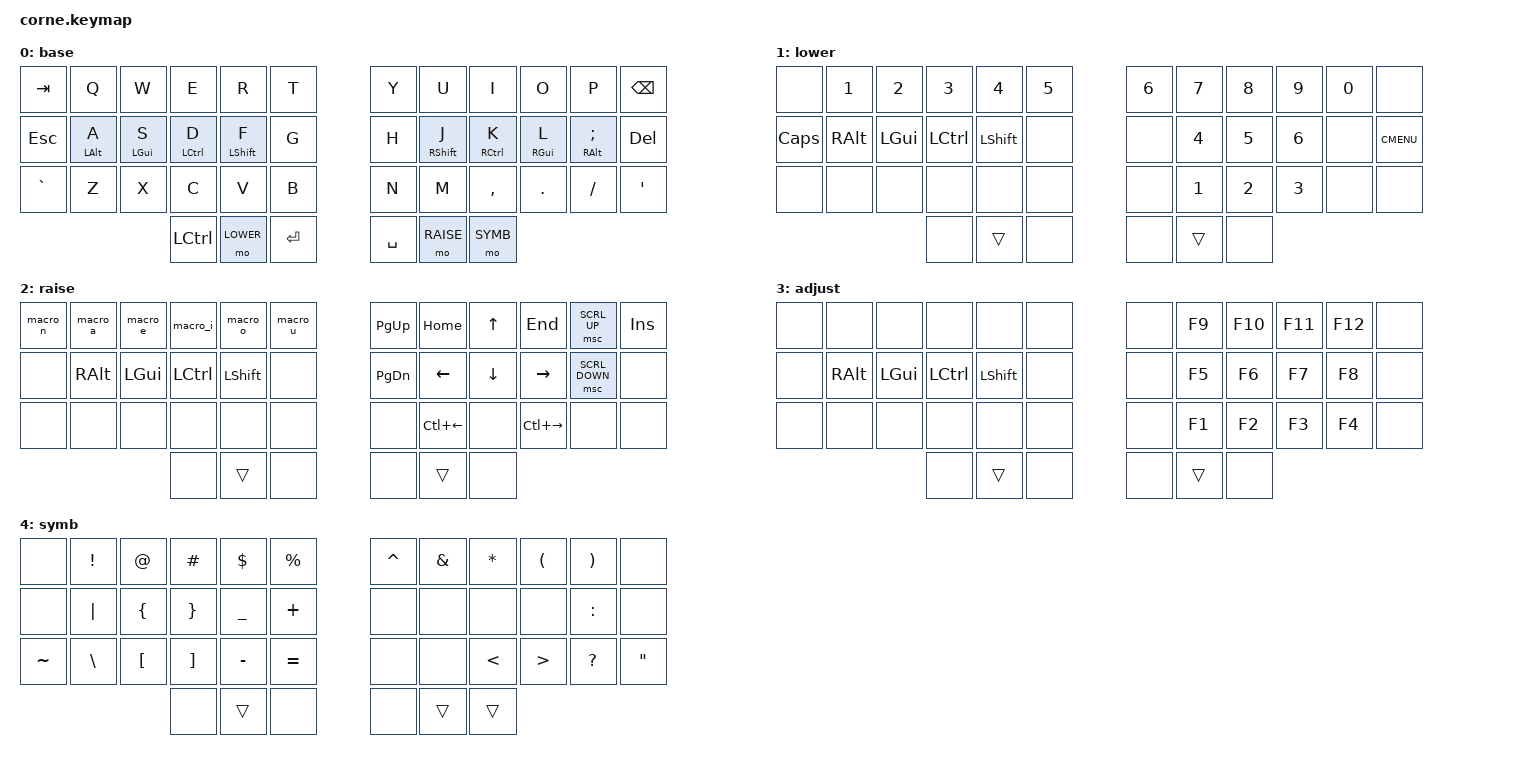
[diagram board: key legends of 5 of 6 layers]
/*
 * Copyright (c) 2020 The ZMK Contributors
 *
 * SPDX-License-Identifier: MIT.
 */

#include <behaviors.dtsi>
#include <dt-bindings/zmk/keys.h>
#include <dt-bindings/zmk/pointing.h>

#define DEFAULT 0
#define LOWER   1
#define RAISE   2
#define ADJUS   3
#define SYMB    4
#define MOUSE   5

/ {
    combos {
        compatible = "zmk,combos";

        cmb_base {
            key-positions = <17 18>;
            bindings = <&to 0>;
        };

        cmb_mouse {
            key-positions = <38 39>;
            bindings = <&to 5>;
        };

        cmb_f5 {
            key-positions = <30 31>;
            bindings = <&kp F5>;
        };

        cmb_f10 {
            key-positions = <31 32>;
            bindings = <&kp F10>;
        };

        cmb_f11 {
            key-positions = <32 33>;
            bindings = <&kp F11>;
        };

        cmb_f12 {
            key-positions = <33 34>;
            bindings = <&kp F12>;
        };
    };

    behaviors {
        hml: homewrow_mods_left {
            label = "HOMEROW_MODS_LEFT_HAND";
            compatible = "zmk,behavior-hold-tap";
            #binding-cells = <2>;
            flavor = "tap-preferred";
            tapping-term-ms = <200>;
            quick-tap-ms = <150>;
            bindings = <&kp>, <&kp>;

            hold-trigger-key-positions = <6 7 8 9 10 11 18 19 20 21 22 23 30 31 32 33 34 35 39 40 41>;
        };

        hmr: homewrow_mods_right {
            label = "HOMEROW_MODS_RIGHT_HAND";
            compatible = "zmk,behavior-hold-tap";
            #binding-cells = <2>;
            flavor = "tap-preferred";
            tapping-term-ms = <200>;
            quick-tap-ms = <150>;
            bindings = <&kp>, <&kp>;

            hold-trigger-key-positions = <0 1 2 3 4 5 12 13 14 15 16 17 24 25 26 27 28 29 36 37 38>;
        };
    };

    conditional_layers {
        compatible = "zmk,conditional-layers";

        tri_layer {
            if-layers = <LOWER RAISE>;
            then-layer = <ADJUS>;
        };
    };

    macros {
        macro_a: macro_a {
            compatible = "zmk,behavior-macro";
            #binding-cells = <0>;
            bindings =
                <&macro_press>,
                <&kp RALT>,
                <&macro_tap>,
                <&kp KP_NUMBER_0 &kp KP_NUMBER_2 &kp KP_NUMBER_2 &kp KP_NUMBER_5>,
                <&macro_release>,
                <&kp RALT>;

            label = "MACRO_A";
        };

        macro_e: macro_e {
            compatible = "zmk,behavior-macro";
            #binding-cells = <0>;
            bindings =
                <&macro_press>,
                <&kp RALT>,
                <&macro_tap>,
                <&kp KP_NUMBER_0 &kp KP_NUMBER_2 &kp KP_NUMBER_3 &kp KP_NUMBER_3>,
                <&macro_release>,
                <&kp RALT>;

            label = "MACRO_E";
        };

        macro_i: macro_i {
            compatible = "zmk,behavior-macro";
            #binding-cells = <0>;
            bindings =
                <&macro_press>,
                <&kp RALT>,
                <&macro_tap>,
                <&kp KP_NUMBER_0 &kp KP_NUMBER_2 &kp KP_NUMBER_3 &kp KP_NUMBER_7>,
                <&macro_release>,
                <&kp RALT>;

            label = "MACRO_I";
        };

        macro_o: macro_o {
            compatible = "zmk,behavior-macro";
            #binding-cells = <0>;
            bindings =
                <&macro_press>,
                <&kp RALT>,
                <&macro_tap>,
                <&kp KP_NUMBER_0 &kp KP_NUMBER_2 &kp KP_NUMBER_4 &kp KP_NUMBER_3>,
                <&macro_release>,
                <&kp RALT>;

            label = "MACRO_O";
        };

        macro_u: macro_u {
            compatible = "zmk,behavior-macro";
            #binding-cells = <0>;
            bindings =
                <&macro_press>,
                <&kp RALT>,
                <&macro_tap>,
                <&kp KP_NUMBER_0 &kp KP_NUMBER_2 &kp KP_NUMBER_5 &kp KP_NUMBER_0>,
                <&macro_release>,
                <&kp RALT>;

            label = "MACRO_U";
        };

        macro_n: macro_n {
            compatible = "zmk,behavior-macro";
            #binding-cells = <0>;
            bindings =
                <&macro_press>,
                <&kp RALT>,
                <&macro_tap>,
                <&kp KP_NUMBER_0 &kp KP_NUMBER_2 &kp KP_NUMBER_4 &kp KP_NUMBER_1>,
                <&macro_release>,
                <&kp RALT>;

            label = "MACRO_N";
        };
    };

    keymap {
        compatible = "zmk,keymap";

        base {
            bindings = <
&kp TAB    &kp Q            &kp W        &kp E         &kp R          &kp T        &kp Y      &kp U          &kp I         &kp O        &kp P                &kp BACKSPACE
&kp ESC    &hml LEFT_ALT A  &hml LGUI S  &hml LCTRL D  &hml LSHIFT F  &kp G        &kp H      &hmr RSHIFT J  &hmr RCTRL K  &hmr RGUI L  &hmr RIGHT_ALT SEMI  &kp DEL
&kp GRAVE  &kp Z            &kp X        &kp C         &kp V          &kp B        &kp N      &kp M          &kp COMMA     &kp DOT      &kp FSLH             &kp SQT
                                         &kp LCTRL     &mo LOWER      &kp ENTER    &kp SPACE  &mo RAISE      &mo SYMB
            >;
        };

        lower {
            bindings = <
&none     &kp N1    &kp N2    &kp N3     &kp N4     &kp N5    &kp N6  &kp N7  &kp N8  &kp N9  &kp N0  &none
&kp CAPS  &kp RALT  &kp LGUI  &kp LCTRL  &kp LSHFT  &none     &none   &kp N4  &kp N5  &kp N6  &none   &kp K_CMENU
&none     &none     &none     &none      &none      &none     &none   &kp N1  &kp N2  &kp N3  &none   &none
                              &none      &trans     &none     &none   &trans  &none
            >;
        };

        raise {
            bindings = <
&macro_n  &macro_a  &macro_e  &macro_i   &macro_o   &macro_u  &kp PG_UP  &kp HOME      &kp UP    &kp END        &msc SCRL_UP    &kp INS
&none     &kp RALT  &kp LGUI  &kp LCTRL  &kp LSHFT  &none     &kp PG_DN  &kp LEFT      &kp DOWN  &kp RIGHT      &msc SCRL_DOWN  &none
&none     &none     &none     &none      &none      &none     &none      &kp LC(LEFT)  &none     &kp LC(RIGHT)  &none           &none
                              &none      &trans     &none     &none      &trans        &none
            >;
        };

        adjust {
            bindings = <
&none  &none     &none     &none      &none      &none    &none  &kp F9  &kp F10  &kp F11  &kp F12  &none
&none  &kp RALT  &kp LGUI  &kp LCTRL  &kp LSHFT  &none    &none  &kp F5  &kp F6   &kp F7   &kp F8   &none
&none  &none     &none     &none      &none      &none    &none  &kp F1  &kp F2   &kp F3   &kp F4   &none
                           &none      &trans     &none    &none  &trans  &none
            >;
        };

        symb {
            bindings = <
&none      &kp EXCL  &kp AT    &kp HASH  &kp DLLR   &kp PRCNT    &kp CARET  &kp AMPS  &kp ASTRK  &kp LPAR  &kp RPAR   &none
&none      &kp PIPE  &kp LBRC  &kp RBRC  &kp UNDER  &kp PLUS     &none      &none     &none      &none     &kp COLON  &none
&kp TILDE  &kp BSLH  &kp LBKT  &kp RBKT  &kp MINUS  &kp EQUAL    &none      &none     &kp LT     &kp GT    &kp QMARK  &kp DOUBLE_QUOTES
                               &none     &trans     &none        &none      &trans    &trans
            >;
        };

        mouse {
            bindings = <
&none  &none  &mkp LCLK       &msc SCRL_UP    &mkp RCLK        &none    &none  &mkp LCLK       &mmv MOVE_UP    &mkp RCLK        &none  &none
&none  &none  &msc SCRL_LEFT  &msc SCRL_DOWN  &msc SCRL_RIGHT  &none    &none  &mmv MOVE_LEFT  &mmv MOVE_DOWN  &mmv MOVE_RIGHT  &none  &none
&none  &none  &none           &none           &none            &none    &none  &none           &none           &none            &none
                              &none           &none            &none    &none  &none           &none
            >;
        };
    };
};
